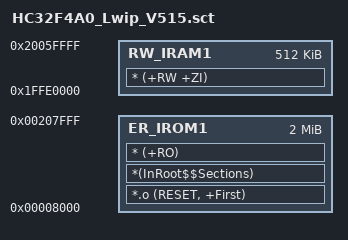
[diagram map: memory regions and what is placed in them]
; *************************************************************
; *** Scatter-Loading Description File generated by uVision ***
; *************************************************************
; 注意: B002/V1兼容前提是升级文件(bin+4字节CRC32)不超过0x64000(400K),
; 否则B002设备升级时备份区写入会擦掉正在运行的代码。当前镜像约0x5F56C。

LR_IROM1 0x00008000 0x00200000  {    ; load region size_region
  ER_IROM1 0x00008000 0x00200000  {  ; load address = execution address
   *.o (RESET, +First)
   *(InRoot$$Sections)
   * (+RO)
  }
  RW_IRAM1 0x1FFE0000 0x00080000  {  ; RW data
   * (+RW +ZI)
  }
}

